AUTOSAR XML (schema 4-0-3)
package /ComponentTypes
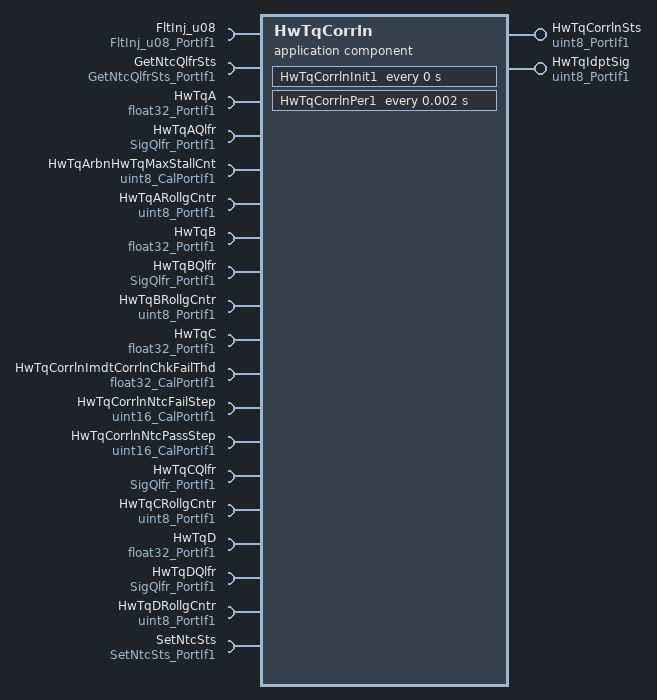
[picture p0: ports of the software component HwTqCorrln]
  application sw component type HwTqCorrln
    provide port HwTqCorrlnSts: nonqueued-sender-com-spec{data-element=Val, init-value=15}, provided-interface=uint8_PortIf1
    provide port HwTqIdptSig: nonqueued-sender-com-spec{data-element=Val, init-value=4}, provided-interface=uint8_PortIf1
    19 x require port:
      FltInj_u08: client-com-spec=Oper, required-interface=FltInj_u08_PortIf1
      GetNtcQlfrSts: client-com-spec=Oper, required-interface=GetNtcQlfrSts_PortIf1
      HwTqA: nonqueued-receiver-com-spec{data-element=Val, filter=data-filter-type=ALWAYS, init-value=0}, required-interface=float32_PortIf1
      HwTqAQlfr: nonqueued-receiver-com-spec{data-element=Val, filter=data-filter-type=ALWAYS, init-value=0}, required-interface=SigQlfr_PortIf1
      HwTqArbnHwTqMaxStallCnt: parameter-require-com-spec{init-value=200, parameter=Val}, required-interface=uint8_CalPortIf1
      HwTqARollgCntr: nonqueued-receiver-com-spec{data-element=Val, filter=data-filter-type=ALWAYS, init-value=0}, required-interface=uint8_PortIf1
      HwTqB: nonqueued-receiver-com-spec{data-element=Val, filter=data-filter-type=ALWAYS, init-value=0}, required-interface=float32_PortIf1
      HwTqBQlfr: nonqueued-receiver-com-spec{data-element=Val, filter=data-filter-type=ALWAYS, init-value=0}, required-interface=SigQlfr_PortIf1
      HwTqBRollgCntr: nonqueued-receiver-com-spec{data-element=Val, filter=data-filter-type=ALWAYS, init-value=0}, required-interface=uint8_PortIf1
      HwTqC: nonqueued-receiver-com-spec{data-element=Val, filter=data-filter-type=ALWAYS, init-value=0}, required-interface=float32_PortIf1
      HwTqCorrlnImdtCorrlnChkFailThd: parameter-require-com-spec{init-value=2.85, parameter=Val}, required-interface=float32_CalPortIf1
      HwTqCorrlnNtcFailStep: parameter-require-com-spec{init-value=3277, parameter=Val}, required-interface=uint16_CalPortIf1
      HwTqCorrlnNtcPassStep: parameter-require-com-spec{init-value=819, parameter=Val}, required-interface=uint16_CalPortIf1
      HwTqCQlfr: nonqueued-receiver-com-spec{data-element=Val, filter=data-filter-type=ALWAYS, init-value=0}, required-interface=SigQlfr_PortIf1
      HwTqCRollgCntr: nonqueued-receiver-com-spec{data-element=Val, filter=data-filter-type=ALWAYS, init-value=0}, required-interface=uint8_PortIf1
      HwTqD: nonqueued-receiver-com-spec{data-element=Val, filter=data-filter-type=ALWAYS, init-value=0}, required-interface=float32_PortIf1
      HwTqDQlfr: nonqueued-receiver-com-spec{data-element=Val, filter=data-filter-type=ALWAYS, init-value=0}, required-interface=SigQlfr_PortIf1
      HwTqDRollgCntr: nonqueued-receiver-com-spec{data-element=Val, filter=data-filter-type=ALWAYS, init-value=0}, required-interface=uint8_PortIf1
      SetNtcSts: client-com-spec=Oper, required-interface=SetNtcSts_PortIf1
    behavior HwTqCorrln_InternalBehavior
      ar-typed-per-instance-memorys:
        10 x data, all with sw-calibration-access=READ-ONLY, type=uint8:
          dHwTqCorrlnAvl
          dHwTqCorrlnImdtCorrlnSts
          HwTqARollgCntrPrev
          HwTqAStallCntrPrev
          HwTqBRollgCntrPrev
          HwTqBStallCntrPrev
          HwTqCRollgCntrPrev
          HwTqCStallCntrPrev
          HwTqDRollgCntrPrev
          HwTqDStallCntrPrev
      timing event HwTqCorrln_InitEvent: start-on-event=HwTqCorrlnInit1, period=0
      timing event TMT_HwTqCorrlnPer1: start-on-event=HwTqCorrlnPer1, period=0.002
      runnable HwTqCorrlnInit1
      runnable HwTqCorrlnPer1
        data-receive-point-by-arguments:
          12 x access:
            REC_HwTqA_Val: accessed-variable=HwTqA.Val
            REC_HwTqAQlfr_Val: accessed-variable=HwTqAQlfr.Val
            REC_HwTqARollgCntr_Val: accessed-variable=HwTqARollgCntr.Val
            REC_HwTqB_Val: accessed-variable=HwTqB.Val
            REC_HwTqBQlfr_Val: accessed-variable=HwTqBQlfr.Val
            REC_HwTqBRollgCntr_Val: accessed-variable=HwTqBRollgCntr.Val
            REC_HwTqC_Val: accessed-variable=HwTqC.Val
            REC_HwTqCQlfr_Val: accessed-variable=HwTqCQlfr.Val
            REC_HwTqCRollgCntr_Val: accessed-variable=HwTqCRollgCntr.Val
            REC_HwTqD_Val: accessed-variable=HwTqD.Val
            REC_HwTqDQlfr_Val: accessed-variable=HwTqDQlfr.Val
            REC_HwTqDRollgCntr_Val: accessed-variable=HwTqDRollgCntr.Val
        data-send-points:
          access SEND_HwTqCorrlnSts_Val: accessed-variable=HwTqCorrlnSts.Val
          access SEND_HwTqIdptSig_Val: accessed-variable=HwTqIdptSig.Val
        sync call SC_FltInj_u08_Oper: operation=FltInj_u08.Oper, timeout=0
        sync call SC_GetNtcQlfrSts_Oper: operation=GetNtcQlfrSts.Oper, timeout=0
        sync call SC_SetNtcSts_Oper: operation=SetNtcSts.Oper, timeout=0
  swc implementation HwTqCorrln_Implementation: behavior=HwTqCorrln_InternalBehavior
    code-descriptors:
      code Default: artifact-descriptors=autosar-engineering-object={short-label=Default, category=SWSRC}
